# ESP32-H4 register map
Vendor: ESPRESSIF SYSTEMS (SHANGHAI) CO., LTD.; Series: ESP32 H-Series; File version: 1
CPU: RV32IMAC r0p0, little endian, no MPU, no FPU, 0 interrupt priority bits
Address unit: 32 bits
Registers are 32-bit, read-write, reset 0x0 unless marked. A register's access mark holds for its fields unless they carry their own. Offsets are from the block's base; [hi:lo] are bit positions; 'fields as' and 'values as' point back to an identical list; <NAME> marks a mode.

## USB0 (part 2 of 4) — USB OTG (On-The-Go)
Base 0x60040000
Same registers: USB1 0x6007F000
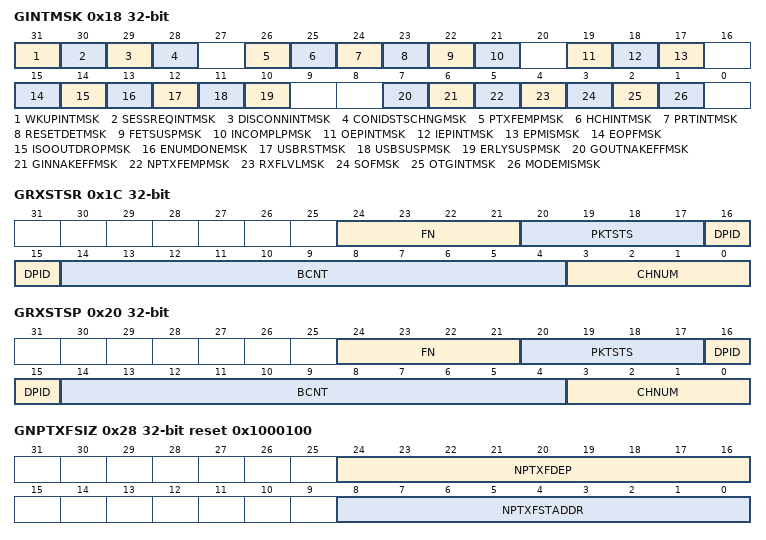
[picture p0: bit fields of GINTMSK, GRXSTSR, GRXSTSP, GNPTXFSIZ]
0x18 GINTMSK — Interrupt Mask Register This register works with the Interrupt Register (GINTSTS) to interrupt the application. When an interrupt bit is masked, the interrupt associated with that bit is not generated. However, the GINTSTS register bit corresponding to that interrupt is still set. Note: The fields of this register change depending on host or device mode.
  [31] WKUPINTMSK — Mode: Host and Device Resume/Remote Wakeup Detected Interrupt Mask (WkUpIntMsk) The WakeUp bit is used for LPM state wake up in a way similar to that of wake up in suspend state.
  [30] SESSREQINTMSK — Mode: Host and Device Session Request/New Session Detected Interrupt Mask (SessReqIntMsk)
  [29] DISCONNINTMSK — Mode: Host and Device Disconnect Detected Interrupt Mask (DisconnIntMsk)
  [28] CONIDSTSCHNGMSK — Mode: Host and Device Connector ID Status Change Mask (ConIDStsChngMsk)
  [26] PTXFEMPMSK — Mode: Host only Periodic TxFIFO Empty Mask (PTxFEmpMsk)
  [25] HCHINTMSK — Mode: Host only Host Channels Interrupt Mask (HChIntMsk)
  [24] PRTINTMSK — Mode: Host only Host Port Interrupt Mask (PrtIntMsk)
  [23] RESETDETMSK — Mode: Device only Reset detected Interrupt Mask (ResetDetMsk)
  [22] FETSUSPMSK — Mode: Device only Data Fetch Suspended Mask (FetSuspMsk)
  [21] INCOMPLPMSK — Incomplete Periodic Transfer Mask (incomplPMsk) Mode: Host only Incomplete Isochronous OUT Transfer Interrupt Mask (incompISOOUTMsk) Mode: Device only
  [19] OEPINTMSK — Mode: Device only OUT Endpoints Interrupt Mask (OEPIntMsk)
  [18] IEPINTMSK — Mode: Device only IN Endpoints Interrupt Mask (IEPIntMsk)
  [17] EPMISMSK — Mode: Device only Endpoint Mismatch Interrupt Mask (EPMisMsk)
  [15] EOPFMSK — Mode: Device only End of Periodic Frame Interrupt Mask (EOPFMsk)
  [14] ISOOUTDROPMSK — Mode: Device only Isochronous OUT Packet Dropped Interrupt Mask (ISOOutDropMsk)
  [13] ENUMDONEMSK — Mode: Device only Enumeration Done Mask (EnumDoneMsk)
  [12] USBRSTMSK — Mode: Device only USB Reset Mask (USBRstMsk)
  [11] USBSUSPMSK — Mode: Device only USB Suspend Mask (USBSuspMsk)
  [10] ERLYSUSPMSK — Mode: Device only Early Suspend Mask (ErlySuspMsk)
  [7] GOUTNAKEFFMSK — Mode: Device only Global OUT NAK Effective Mask (GOUTNakEffMsk)
  [6] GINNAKEFFMSK — Mode: Device only, Global Non-periodic IN NAK Effective Mask (GINNakEffMsk)
  [5] NPTXFEMPMSK — Mode: Host and Device Non-periodic TxFIFO Empty Mask (NPTxFEmpMsk)
  [4] RXFLVLMSK — Mode: Host and Device Receive FIFO Non-Empty Mask (RxFLvlMsk)
  [3] SOFMSK — Mode: Host and Device Start of (micro)Frame Mask (SofMsk)
  [2] OTGINTMSK — Mode: Host and Device OTG Interrupt Mask (OTGIntMsk)
  [1] MODEMISMSK — Mode: Host and Device Mode Mismatch Interrupt Mask (ModeMisMsk)
0x1C GRXSTSR ro — Receive Status Debug Read Register A read to the Receive Status Debug Read register returns the contents of the top of the Receive FIFO. The receive status contents must be interpreted differently in Host and Device modes. The core ignores the receive status read when the receive FIFO is empty and returns a value of 32'h0000_0000. Note: - Use of these fields vary based on whether the core is functioning as a host or a device. - Do not read this register's reset value before configuring the core because the read value is 'X' in the simulation.
  [24:21] FN — Mode: Device only Frame Number (FN) This is the least significant 4 bits of the (micro)Frame number in which the packet is received on the USB. This field is supported only when isochronous OUT endpoints are supported.
  [20:17] PKTSTS — Packet Status (PktSts) indicates the status of the received packet. In host mode, - 4'b0010: IN data packet received - 4'b0011: IN transfer completed (triggers an interrupt) - 4'b0101: Data toggle error (triggers an interrupt) - 4'b0111: Channel halted (triggers an interrupt) - Others: Reserved Reset:4'b0 In device mode, - 4'b0001: Global OUT NAK (triggers an interrupt) - 4'b0010: OUT data packet received - 4'b0011: OUT transfer completed (triggers an interrupt) - 4'b0100: SETUP transaction completed (triggers an interrupt) - 4'b0110: SETUP data packet received - Others: Reserved Reset:4'h0
  [16:15] DPID — Data PID (DPID) In host mode, indicates the Data PID of the received packet. In device mode, indicates the Data PID of the received OUT data packet. - 2'b00: DATA0 - 2'b10: DATA1 - 2'b01: DATA2 - 2'b11: MDATA Reset: 2'h0
  [14:4] BCNT — Byte Count (BCnt) In host mode, indicates the byte count of the received IN data packet. In device mode, indicates the byte count of the received data packet.
  [3:0] CHNUM — Channel Number (ChNum) Mode: Host only Indicates the channel number to which the current received packet belongs. Endpoint Number (EPNum) Mode: Device only Indicates the endpoint number to which the current received packet belongs.
0x20 GRXSTSP ro — Receive Status Read/Pop Register A read to the Receive Status Read and Pop register returns the contents of the top of the Receive FIFO and additionally pops the top data entry out of the RxFIFO. The receive status contents must be interpreted differently in Host and Device modes. The core ignores the receive status pop/read when the receive FIFO is empty and returns a value of 32'h0000_0000. The application must only pop the Receive Status FIFO when the Receive FIFO Non-Empty bit of the Core Interrupt register (GINTSTS.RxFLvl) is asserted. Note: - Use of these fields vary based on whether the core is functioning as a host or a device. - Do not read this register's reset value before configuring the core because the read value is 'X' in the simulation.
  fields as GRXSTSR
0x24 GRXFSIZ reset 0x100 — Receive FIFO Size Register The application can program the RAM size that must be allocated to the RxFIFO.
  [8:0] RXFDEP — Mode: Host and Device RxFIFO Depth (RxFDep) This value is in terms of 32-bit words. - Minimum value is 16 - Maximum value is 32,768 The power-on reset value of this register is specified as the Largest Rx Data FIFO Depth during configuration. If Enable Dynamic FIFO Sizing is selected in coreConsultant, these flops are optimized, and reads return the power-on value. If Enable Dynamic FIFO Sizing is selected in coreConsultant, you can write a new value in this field. Programmed values must not exceed the power-on value.
0x28 GNPTXFSIZ reset 0x1000100 — Non-periodic Transmit FIFO Size Register The application can program the RAM size and the memory start address for the Non-periodic TxFIFO Note: The fields of this register change depending on host or device mode.
  [24:16] NPTXFDEP — Mode: Host only Non-periodic TxFIFO Depth (NPTxFDep) For host mode, this field is always valid. For device mode, this field is valid only when OTG_EN_DED_TX_FIFO=0. This value is in terms of 32-bit words. - Minimum value is 16 - Maximum value is 32,768 This attribute of field is determined during coreConsultant configuration by Enable Dynamic FIFO Sizing? (OTG_DFIFO_DYNAMIC): - OTG_DFIFO_DYNAMIC = 0: These flops are optimized, and reads return the power-on value. - OTG_DFIFO_DYNAMIC = 1: The application can write a new value in this field. Programmed values must not exceed the power-on value set in coreConsultant. The power-on reset value of this field is specified during coreConsultant configuration as Largest IN Endpoint FIFO 0 Depth (parameter OTG_TX_DINEP_DFIFO_DEPTH_0).
  [8:0] NPTXFSTADDR — Non-periodic Transmit RAM Start Address (NPTxFStAddr) For host mode, this field is always valid. This field contains the memory start address for Non-periodic Transmit FIFO RAM. - This field is determined during coreConsultant configuration by Enable Dynamic FIFO Sizing? (OTG_DFIFO_DYNAMIC):OTG_DFIFO_DYNAMIC = 0 These flops are optimized, and reads return the power-on value. - OTG_DFIFO_DYNAMIC = 1 The application can write a new value in this field. Programmed values must not exceed the power-on value set in coreConsultant. Programmed values must not exceed the power-on value set in coreConsultant. The power-on reset value of this field is specified during coreConsultant configuration by Largest Rx Data FIFO Depth (parameter OTG_RX_DFIFO_DEPTH).
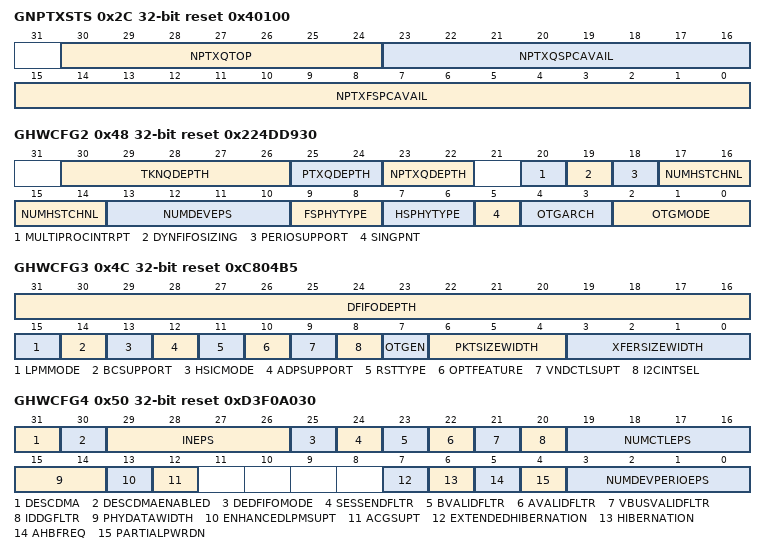
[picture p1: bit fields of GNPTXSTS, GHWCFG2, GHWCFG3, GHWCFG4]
0x2C GNPTXSTS ro reset 0x40100 — Non-periodic Transmit FIFO/Queue Status Register In Device mode, this register is valid only in Shared FIFO operation. This read-only register contains the free space information for the Non-periodic TxFIFO and the Non-periodic Transmit Request Queue.
  [30:24] NPTXQTOP — Top of the Non-periodic Transmit Request Queue (NPTxQTop) Entry in the Non-periodic Tx Request Queue that is currently being processed by the MAC. - Bits [30:27]: Channel/endpoint number - Bits [26:25]: - 2'b00: IN/OUT token -- 2'b01: Zero-length transmit packet (device IN/host OUT) -- 2'b10: PING/CSPLIT token -- 2'b11: Channel halt command - Bit [24]: Terminate (last Entry for selected channel/endpoint) Reset: 7'h0
  [23:16] NPTXQSPCAVAIL — Non-periodic Transmit Request Queue Space Available (NPTxQSpcAvail) Indicates the amount of free space available in the Non-periodic Transmit Request Queue. This queue holds both IN and OUT requests in Host mode. Device mode has only IN requests. - 8'h0: Non-periodic Transmit Request Queue is full - 8'h1: 1 location available - 8'h2: 2 locations available - n: n locations available (0 <= n <= 8) - Others: Reserved Reset: Configurable
  [15:0] NPTXFSPCAVAIL — Non-periodic TxFIFO Space Avail (NPTxFSpcAvail) Indicates the amount of free space available in the Non-periodic TxFIFO. Values are in terms of 32-bit words. - 16'h0: Non-periodic TxFIFO is full - 16'h1: 1 word available - 16'h2: 2 words available - 16'hn: n words available (where 0 <= n <= 32,768) - 16'h8000: 32,768 words available - Others: Reserved Reset: Configurable
0x40 GSNPSID ro reset 0x4F54400A — Synopsys ID Register This read-only register contains the release number of the core being used.
  [31:0] SYNOPSYSID — Release number of the controller being used currently.
0x44 GHWCFG1 ro — User Hardware Configuration 1 Register This register contains the logical endpoint direction(s) selected using coreConsultant.
  [31:0] EPDIR — This 32-bit field uses two bits per endpoint to determine the endpoint direction. Endpoint - Bits [31:30]: Endpoint 15 direction - Bits [29:28]: Endpoint 14 direction ... - Bits [3:2]: Endpoint 1 direction - Bits[1:0]: Endpoint 0 direction (always BIDIR) Direction - 2'b00: BIDIR (IN and OUT) endpoint - 2'b01: IN endpoint - 2'b10: OUT endpoint - 2'b11: Reserved Note: This field is configured using the OTG_EP_DIR_1(n) parameter.
0x48 GHWCFG2 ro reset 0x224DD930 — User Hardware Configuration 2 Register This register contains configuration options selected using coreConsultant.
  [30:26] TKNQDEPTH — Device Mode IN Token Sequence Learning Queue Depth (TknQDepth) Range: 0-30 Note: This field is configured using the OTG_TOKEN_QUEUE_DEPTH parameter.
  [25:24] PTXQDEPTH — Host Mode Periodic Request Queue Depth (PTxQDepth) - 2'b00: 2 - 2'b01: 4 - 2'b10: 8 - 2'b11:16 Note: This field is configured using the OTG_PERIO_TX_QUEUE_DEPTH parameter.
  [23:22] NPTXQDEPTH — Non-periodic Request Queue Depth (NPTxQDepth) - 2'b00: 2 - 2'b01: 4 - 2'b10: 8 - Others: Reserved Note: This field is configured using the OTG_NPERIO_TX_QUEUE_DEPTH parameter.
  [20] MULTIPROCINTRPT — Multi Processor Interrupt Enabled (MultiProcIntrpt) - 1'b0: No - 1'b1: Yes Note: This field is configured using the OTG_MULTI_PROC_INTRPT parameter.
  [19] DYNFIFOSIZING — Dynamic FIFO Sizing Enabled (DynFifoSizing) - 1'b0: No - 1'b1: Yes Note: This field is configured using the OTG_DFIFO_DYNAMIC parameter.
  [18] PERIOSUPPORT — Periodic OUT Channels Supported in Host Mode (PerioSupport) - 1'b0: No - 1'b1: Yes Note: This field is configured using the OTG_EN_PERIO_HOST parameter.
  [17:14] NUMHSTCHNL — Number of Host Channels (NumHstChnl) Indicates the number of host channels supported by the core in Host mode. The range of this field is 0-15: 0 specifies 1 channel, 15 specifies 16 channels. Note: This field is configured using the OTG_NUM_HOST_CHAN parameter.
  [13:10] NUMDEVEPS — Number of Device Endpoints (NumDevEps) Indicates the number of device endpoints supported by the core in Device mode. The range of this field is 0-15. Note: This field is configured using the OTG_NUM_EPS parameter.
  [9:8] FSPHYTYPE — Full-Speed PHY Interface Type (FSPhyType) - 2'b00: Full-speed interface not supported - 2'b01: Dedicated full-speed interface - 2'b10: FS pins shared with UTMI+ pins - 2'b11: FS pins shared with ULPI pins Note: This field is configured using the OTG_FSPHY_INTERFACE parameter.
  [7:6] HSPHYTYPE — High-Speed PHY Interface Type (HSPhyType) - 2'b00: High-Speed interface not supported - 2'b01: UTMI+ - 2'b10: ULPI - 2'b11: UTMI+ and ULPI Note: This field is configured using the OTG_HSPHY_INTERFACE parameter.
  [5] SINGPNT — Point-to-Point (SingPnt) - 1'b0: Multi-point application (hub and split support) - 1'b1: Single-point application (no hub and split support) Note: This field is configured using the OTG_SINGLE_POINT parameter.
  [4:3] OTGARCH — Architecture (OtgArch) - 2'b00: Slave-Only - 2'b01: External DMA - 2'b10: Internal DMA - Others: Reserved Note: This field is configured using the OTG_ARCHITECTURE parameter.
  [2:0] OTGMODE — Mode of Operation (OtgMode) - 3'b000: HNP- and SRP-Capable OTG (Host & Device) - 3'b001: SRP-Capable OTG (Host & Device) - 3'b010: Non-HNP and Non-SRP Capable OTG (Host and Device) - 3'b011: SRP-Capable Device - 3'b100: Non-OTG Device - 3'b101: SRP-Capable Host - 3'b110: Non-OTG Host - Others: Reserved Note: This field is configured using the OTG_MODE parameter.
0x4C GHWCFG3 ro reset 0xC804B5 — User Hardware Configuration 3 Register
  [31:16] DFIFODEPTH — DFIFO Depth (DfifoDepth - EP_LOC_CNT) This value is in terms of 32-bit words. - Minimum value is 32 - Maximum value is 32,768 Note: This field is configured using the OTG_DFIFO_DEPTH parameter. For more information on EP_LOC_CNT, see the Endpoint Information Controller (EPINFO_CTL) section.
  [15] LPMMODE — LPM mode specified for Mode of Operation.
  [14] BCSUPPORT — This bit indicates the controller support for Battery Charger. - 0 - No Battery Charger Support - 1 - Battery Charger support present
  [13] HSICMODE — HSIC mode specified for Mode of Operation Value Range: 0 - 1 - 1: HSIC-capable with shared UTMI PHY interface - 0: Non-HSIC-capable
  [12] ADPSUPPORT — This bit indicates whether ADP logic is present within or external to the controller - 0: No ADP logic present with the controller - 1: ADP logic is present along with the controller.
  [11] RSTTYPE — Reset Style for Clocked always Blocks in RTL (RstType) - 1'b0: Asynchronous reset is used in the controller - 1'b1: Synchronous reset is used in the controller Note: This field is configured using the OTG_SYNC_RESET_TYPE parameter.
  [10] OPTFEATURE — Optional Features Removed (OptFeature) Indicates whether the User ID register, GPIO interface ports, and SOF toggle and counter ports were removed for gate count optimization by enabling Remove Optional Features. - 1'b0: No - 1'b1: Yes Note: This field is configured using the OTG_RM_OPT_FEATURES parameter.
  [9] VNDCTLSUPT — Vendor Control Interface Support (VndctlSupt) - 1'b0: Vendor Control Interface is not available on the core. - 1'b1: Vendor Control Interface is available. Note: This field is configured using the OTG_VENDOR_CTL_INTERFACE parameter.
  [8] I2CINTSEL — I2C Selection (I2CIntSel) - 1'b0: I2C Interface is not available on the controller. - 1'b1: I2C Interface is available on the controller. Note: This field is configured using the OTG_I2C_INTERFACE parameter.
  [7] OTGEN — OTG Function Enabled (OtgEn) The application uses this bit to indicate the OTG capabilities of the controller . - 1'b0: Not OTG capable - 1'b1: OTG Capable Note: This field is configured using the OTG_MODE parameter.
  [6:4] PKTSIZEWIDTH — Width of Packet Size Counters (PktSizeWidth) - 3'b000: 4 bits - 3'b001: 5 bits - 3'b010: 6 bits - 3'b011: 7 bits - 3'b100: 8 bits - 3'b101: 9 bits - 3'b110: 10 bits - Others: Reserved Note: This field is configured using the OTG_PACKET_COUNT_WIDTH parameter.
  [3:0] XFERSIZEWIDTH — Width of Transfer Size Counters (XferSizeWidth) - 4'b0000: 11 bits - 4'b0001: 12 bits ... - 4'b1000: 19 bits - Others: Reserved Note: This field is configured using the OTG_PACKET_COUNT_WIDTH parameter.
0x50 GHWCFG4 ro reset 0xD3F0A030 — User Hardware Configuration 4 Register Note Bit [31] is available only when Scatter/Gather DMA mode is enabled. When Scatter/Gather DMA mode is disabled, this field is reserved.
  [31] DESCDMA — Scatter/Gather DMA configuration - 1'b0: Non Dynamic configuration - 1'b1: Dynamic configuration Note: This field is configured using the OTG_EN_DESC_DMA parameter.
  [30] DESCDMAENABLED — Scatter/Gather DMA configuration - 1'b0: Non-Scatter/Gather DMA configuration - 1'b1: Scatter/Gather DMA configuration
  [29:26] INEPS — Number of Device Mode IN Endpoints Including Control Endpoints (INEps) - 0: 1 IN Endpoint - 1: 2 IN Endpoints .... - 15: 16 IN Endpoints
  [25] DEDFIFOMODE — Enable Dedicated Transmit FIFO for device IN Endpoints (DedFifoMode) - 1'b0 : Dedicated Transmit FIFO Operation not enabled. - 1'b1 : Dedicated Transmit FIFO Operation enabled.
  [24] SESSENDFLTR — session_end Filter Enabled (SessEndFltr) - 1'b0: No filter - 1'b1: Filter
  [23] BVALIDFLTR — b_valid Filter Enabled (BValidFltr) - 1'b0: No filter - 1'b1: Filter
  [22] AVALIDFLTR — a_valid Filter Enabled (AValidFltr) - 1'b0: No filter - 1'b1: Filter
  [21] VBUSVALIDFLTR — VBUS Valid Filter Enabled (VBusValidFltr) - 1'b0: No filter - 1'b1: Filter
  [20] IDDGFLTR — IDDIG Filter Enable (IddgFltr) - 1'b0: No filter - 1'b1: Filter
  [19:16] NUMCTLEPS — Number of Device Mode Control Endpoints in Addition to Endpoint 0 (NumCtlEps) Range: 0-15
  [15:14] PHYDATAWIDTH — UTMI+ PHY/ULPI-to-Internal UTMI+ Wrapper Data Width (PhyDataWidth)<vr>When a ULPI PHY is used, an internal wrapper converts ULPI to UTMI+. - 2'b00: 8 bits - 2'b01: 16 bits - 2'b10: 8/16 bits, software selectable - Others: Reserved
  [13] ENHANCEDLPMSUPT — Enhanced LPM Support (EnhancedLPMSupt) This bit indicates that the controller supports the following behavior: L1 Entry Behavior based on FIFO Status - TX FIFO - Accept L1 Request even if ISOC OUT TX FIFO is not empty. - Reject L1 Request if Non-Periodic TX FIFO is not empty. - Ensure application can flush the TX FIFO while the Controller is in L1. - RX FIFO - Accept L1 Request even if RX FIFO (common to Periodic and Non-Periodic) is not empty. - Accept L1 Request but delay SLEEPM assertion until RX SINK Buffer is empty. Prevent L1 Entry if a Control Transfer is in progress on any Control Endpoint. Ability to Flush TxFIFO even if PHY Clock is gated.
  [12] ACGSUPT — Active Clock Gating Support This bit indicates that the controller supports the Dynamic (Switching) Power Reduction during periods when there is no USB and AHB Traffic. - 1'b0: Active Clock Gating is not enabled. - 1'b1: Active Clock Gating Enabled.
  [7] EXTENDEDHIBERNATION — Enable Hibernation - 1'b0: Extended Hibernation feature not enabled - 1'b1: Extended Hibernation feature enabled
  [6] HIBERNATION — Enable Hibernation (Hibernation) - 1'b0: Hibernation feature not enabled - 1'b1: Hibernation feature enabled
  [5] AHBFREQ — Minimum AHB Frequency Less Than 60 MHz (AhbFreq) - 1'b0: No - 1'b1: Yes
  [4] PARTIALPWRDN — Enable Partial Power Down (PartialPwrDn) - 1'b0: Partial Power Down Not Enabled - 1'b1: Partial Power Down Enabled
  [3:0] NUMDEVPERIOEPS — Number of Device Mode Periodic IN Endpoints (NumDevPerioEps) Range: 0-15
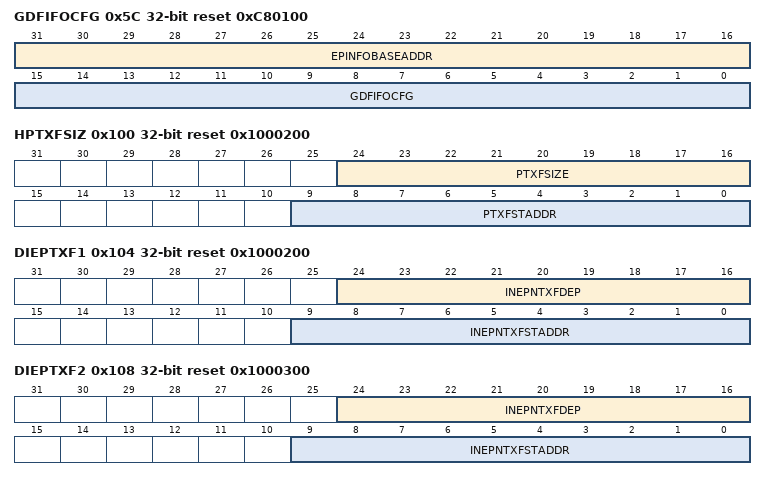
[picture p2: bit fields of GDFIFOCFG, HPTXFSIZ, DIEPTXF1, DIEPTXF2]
0x5C GDFIFOCFG reset 0xC80100 — Global DFIFO Configuration Register
  [31:16] EPINFOBASEADDR — EPInfoBaseAddr This field provides the start address of the EP info controller.
  [15:0] GDFIFOCFG — GDFIFOCfg This field is for dynamic programming of the DFIFO Size. This value takes effect only when the application programs a non zero value to this register. The value programmed must conform to the guidelines described in 'FIFO RAM Allocation'. The core does not have any corrective logic if the FIFO sizes are programmed incorrectly.
0x100 HPTXFSIZ reset 0x1000200 — Host Periodic Transmit FIFO Size Register This register holds the size and the memory start address of the Periodic TxFIFO. Note: Read the reset value of this register only after the following conditions: - If IDDIG_FILTER is disabled, read only after PHY clock is stable. - If IDDIG_FILTER is enabled, read only after the filter timer expires.
  [24:16] PTXFSIZE — Host Periodic TxFIFO Depth (PTxFSize) This value is in terms of 32-bit words. - Minimum value is 16 - Maximum value is 32,768 The power-on reset value of this register is specified as the Largest Host Mode Periodic Tx Data FIFO Depth. - If Enable Dynamic FIFO Sizing? was deselected in coreConsultant (parameter OTG_DFIFO_DYNAMIC = 0), these flops are optimized, and reads return the power-on value. - If Enable Dynamic FIFO Sizing? was selected in coreConsultant (parameter OTG_DFIFO_DYNAMIC = 1), you can write a new value in this field. Programmed values must not exceed the power-on value set in coreConsultant.
  [9:0] PTXFSTADDR — Host Periodic TxFIFO Start Address (PTxFStAddr) The power-on reset value of this register is the sum of the Largest Rx Data FIFO Depth and Largest Non-periodic Tx Data FIFO Depth.These parameters are: In shared FIFO operation: - OTG_RX_DFIFO_DEPTH + OTG_TX_NPERIO_DFIFO_DEPTH In dedicated FIFO mode: - OTG_RX_DFIFO_DEPTH + OTG_TX_HNPERIO_DFIFO_DEPTH If Enable Dynamic FIFO Sizing? was deselected in coreConsultant (parameter OTG_DFIFO_DYNAMIC = 0), these flops are optimized, and reads return the power-on value. If Enable Dynamic FIFO Sizing? was selected in coreConsultant (parameter OTG_DFIFO_DYNAMIC = 1), you can write a new value in this field. Programmed values must not exceed the power-on value set in coreConsultant.
0x104 DIEPTXF1 reset 0x1000200 — Device IN Endpoint Transmit FIFO Size Register $i This register is valid only in dedicated FIFO mode (OTG_EN_DED_TX_FIFO=1). It holds the size and memory start address of IN endpoint TxFIFOs implemented in Device mode. Each FIFO holds the data for one IN endpoint. This register is repeated for instantiated IN endpoint FIFOs 1 to 15. For IN endpoint FIFO 0, use GNPTXFSIZ register for programming the size and memory start address.
  [24:16] INEPNTXFDEP — IN Endpoint TxFIFO Depth (INEPnTxFDep) This value is in terms of 32-bit words. - Minimum value is 16 - Maximum value is 32,768 The power-on reset value of this register is specified as the Largest IN Endpoint FIFO number Depth (parameter OTG_TX_DINEP_DFIFO_DEPTH_n) during coreConsultant configuration (0 < i <= 15). - If Enable Dynamic FIFO Sizing? was deselected in coreConsultant (parameter OTG_DFIFO_DYNAMIC = 0), these flops are optimized, and reads return the power-on value. - If Enable Dynamic FIFO Sizing? was selected in coreConsultant (parameter OTG_DFIFO_DYNAMIC = 1), you can write a new value in this field. . Programmed values must not exceed the power-on value
  [9:0] INEPNTXFSTADDR — IN Endpoint FIFOn Transmit RAM Start Address (INEPnTxFStAddr) This field contains the memory start address for IN endpoint Transmit FIFOn (0<n< = 15). The power-on reset value of this register is specified as the Largest Rx Data FIFO Depth. The power-on reset value of this register is calculated according to the following formula: OTG_RX_DFIFO_DEPTH + SUM of OTG_TX_DINEP_DFIFO_DEPTH_'i' (where x = 0 to n 1) If at POR the calculated value (C) exceeds 65535, then the Reset value becomes Reset Value(A) = (C 65536). Example: If start address of IN endpoint FIFO 1 is OTG_RX_DFIFO_DEPTH + OTG_TX_DINEP_DFIFO_DEPTH_ 0 and start address of IN endpoint FIFO 2 is OTG_RX_DFIFO_DEPTH + OTG_TX_DINEP_DFIFO_DEPTH_ 0 + OTG_TX_DINEP_DFIFO_DEPTH_ 1. - If Enable Dynamic FIFO Sizing is deselected in coreConsultant (OTG_DFIFO_DYNAMIC = 0), this field is read-only and read value is the power-on reset value. - If Enable Dynamic FIFO Sizing is selected in coreConsultant (OTG_DFIFO_DYNAMIC = 1), and you have calculated or programmed a new value for RxFIFO depth or TX FIFO depths, you can program their values according to the above formula. Programmed values must not exceed the power-on value set in coreConsultant.
0x108 DIEPTXF2 reset 0x1000300 — Device IN Endpoint Transmit FIFO Size Register $i This register is valid only in dedicated FIFO mode (OTG_EN_DED_TX_FIFO=1). It holds the size and memory start address of IN endpoint TxFIFOs implemented in Device mode. Each FIFO holds the data for one IN endpoint. This register is repeated for instantiated IN endpoint FIFOs 1 to 15. For IN endpoint FIFO 0, use GNPTXFSIZ register for programming the size and memory start address.
  fields as DIEPTXF1
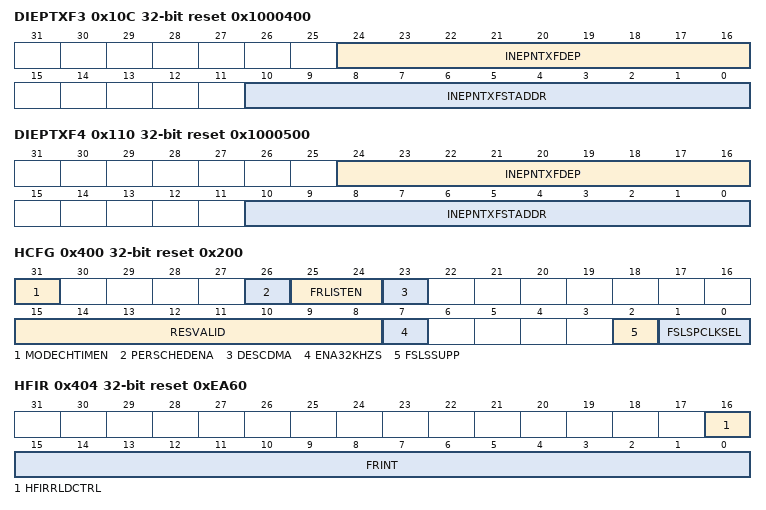
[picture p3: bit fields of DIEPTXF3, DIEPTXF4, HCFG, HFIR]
0x10C DIEPTXF3 reset 0x1000400 — Device IN Endpoint Transmit FIFO Size Register $i This register is valid only in dedicated FIFO mode (OTG_EN_DED_TX_FIFO=1). It holds the size and memory start address of IN endpoint TxFIFOs implemented in Device mode. Each FIFO holds the data for one IN endpoint. This register is repeated for instantiated IN endpoint FIFOs 1 to 15. For IN endpoint FIFO 0, use GNPTXFSIZ register for programming the size and memory start address.
  [24:16] INEPNTXFDEP — IN Endpoint TxFIFO Depth (INEPnTxFDep) This value is in terms of 32-bit words. - Minimum value is 16 - Maximum value is 32,768 The power-on reset value of this register is specified as the Largest IN Endpoint FIFO number Depth (parameter OTG_TX_DINEP_DFIFO_DEPTH_n) during coreConsultant configuration (0 < i <= 15). - If Enable Dynamic FIFO Sizing? was deselected in coreConsultant (parameter OTG_DFIFO_DYNAMIC = 0), these flops are optimized, and reads return the power-on value. - If Enable Dynamic FIFO Sizing? was selected in coreConsultant (parameter OTG_DFIFO_DYNAMIC = 1), you can write a new value in this field. . Programmed values must not exceed the power-on value
  [10:0] INEPNTXFSTADDR — IN Endpoint FIFOn Transmit RAM Start Address (INEPnTxFStAddr) This field contains the memory start address for IN endpoint Transmit FIFOn (0<n< = 15). The power-on reset value of this register is specified as the Largest Rx Data FIFO Depth. The power-on reset value of this register is calculated according to the following formula: OTG_RX_DFIFO_DEPTH + SUM of OTG_TX_DINEP_DFIFO_DEPTH_'i' (where x = 0 to n 1) If at POR the calculated value (C) exceeds 65535, then the Reset value becomes Reset Value(A) = (C 65536). Example: If start address of IN endpoint FIFO 1 is OTG_RX_DFIFO_DEPTH + OTG_TX_DINEP_DFIFO_DEPTH_ 0 and start address of IN endpoint FIFO 2 is OTG_RX_DFIFO_DEPTH + OTG_TX_DINEP_DFIFO_DEPTH_ 0 + OTG_TX_DINEP_DFIFO_DEPTH_ 1. - If Enable Dynamic FIFO Sizing is deselected in coreConsultant (OTG_DFIFO_DYNAMIC = 0), this field is read-only and read value is the power-on reset value. - If Enable Dynamic FIFO Sizing is selected in coreConsultant (OTG_DFIFO_DYNAMIC = 1), and you have calculated or programmed a new value for RxFIFO depth or TX FIFO depths, you can program their values according to the above formula. Programmed values must not exceed the power-on value set in coreConsultant.
0x110 DIEPTXF4 reset 0x1000500 — Device IN Endpoint Transmit FIFO Size Register $i This register is valid only in dedicated FIFO mode (OTG_EN_DED_TX_FIFO=1). It holds the size and memory start address of IN endpoint TxFIFOs implemented in Device mode. Each FIFO holds the data for one IN endpoint. This register is repeated for instantiated IN endpoint FIFOs 1 to 15. For IN endpoint FIFO 0, use GNPTXFSIZ register for programming the size and memory start address.
  fields as DIEPTXF3
0x400 HCFG reset 0x200 — Host Configuration Register
  [31] MODECHTIMEN — Mode Change Ready Timer Enable (ModeChTimEn) This bit is used to enable/disable the Host core to wait 200 PHY clock cycles at the end of Resume to change the opmode signal to the PHY to 00 after Suspend or LPM. - 1'b0 : The Host core waits for either 200 PHY clock cycles or a linestate of SE0 at the end of resume to the change the opmode from 2'b10 to 2'b00 - 1'b1 : The Host core waits only for a linstate of SE0 at the end of resume to change the opmode from 2'b10 to 2'b00.
  [26] PERSCHEDENA — Enable Periodic Scheduling (PerSchedEna): Applicable in host DDMA mode only. Enables periodic scheduling within the core. Initially, the bit is reset. The core will not process any periodic channels. As soon as this bit is set, the core will get ready to start scheduling periodic channels and sets HCFG.PerSchedStat. The setting of HCFG.PerSchedStat indicates the core has enabled periodic scheduling. Once HCFG.PerSchedEna is set, the application is not supposed to again reset the bit unless HCFG.PerSchedStat is set. As soon as this bit is reset, the core will get ready to stop scheduling periodic channels and resets HCFG.PerSchedStat.
  [25:24] FRLISTEN — Frame List Entries(FrListEn) The value in the register specifies the number of entries in the Frame list. This field is valid only in Scatter/Gather DMA mode. - 2'b00: 8 Entries - 2'b01: 16 Entries - 2'b10: 32 Entries - 2'b11: 64 Entries
  [23] DESCDMA — Enable Scatter/gather DMA in Host mode (DescDMA) When the Scatter/Gather DMA option selected during configuration of the RTL, the application can set this bit during initialization to enable the Scatter/Gather DMA operation. Note: This bit must be modified only once after a reset. The following combinations are available for programming: - GAHBCFG.DMAEn=0,HCFG.DescDMA=0 => Slave mode - GAHBCFG.DMAEn=0,HCFG.DescDMA=1 => Invalid - GAHBCFG.DMAEn=1,HCFG.DescDMA=0 => Buffered DMA mode - GAHBCFG.DMAEn=1,HCFG.DescDMA=1 => Scatter/Gather DMA mode
  [15:8] RESVALID — Resume Validation Period (ResValid) This field is effective only when HCFG.Ena32KHzS is set. It will control the resume period when the core resumes from suspend. The core counts for 'ResValid' number of clock cycles to detect a valid resume when this is set.
  [7] ENA32KHZS — Enable 32 KHz Suspend mode (Ena32KHzS) This bit can be set only in FS PHY interface is selected. Else, this bit needs to be set to zero. When FS PHY interface is chosen and this bit is set, the core expects that the PHY clock during Suspend is switched from 48 MHz to 32 KHz.
  [2] FSLSSUPP — FS- and LS-Only Support (FSLSSupp) The application uses this bit to control the core's enumeration speed. Using this bit, the application can make the core enumerate as a FS host, even If the connected device supports HS traffic. Do not make changes to this field after initial programming. - 1'b0: HS/FS/LS, based on the maximum speed supported by the connected device - 1'b1: FS/LS-only, even If the connected device can support HS
  [1:0] FSLSPCLKSEL — FS/LS PHY Clock Select (FSLSPclkSel) When the core is in FS Host mode - 2'b00: PHY clock is running at 30/60 MHz - 2'b01: PHY clock is running at 48 MHz - Others: Reserved When the core is in LS Host mode - 2'b00: PHY clock is running at 30/60 MHz. When the UTMI+/ULPI PHY Low Power mode is not selected, use 30/60 MHz. - 2'b01: PHY clock is running at 48 MHz. When the UTMI+ PHY Low Power mode is selected, use 48MHz If the PHY supplies a 48 MHz clock during LS mode. - 2'b10: PHY clock is running at 6 MHz. In USB 1.1 FS mode, use 6 MHz when the UTMI+ PHY Low Power mode is selected and the PHY supplies a 6 MHz clock during LS mode. If you select a 6 MHz clock during LS mode, you must do a soft reset. - 2'b11: Reserved Notes: - When Core in FS mode, the internal and external clocks have the same frequency. - When Core in LS mode, -- If FSLSPclkSel = 2'b00: Internal and external clocks have the same frequency -- If FSLSPclkSel = 2'b10: Internal clock is the divided by eight version of external 48 MHz clock
0x404 HFIR reset 0xEA60 — Host Frame Interval Register
  [16] HFIRRLDCTRL — Reload Control (HFIRRldCtrl) This bit allows dynamic reloading of the HFIR register during run time. - 1'b0 : The HFIR cannot be reloaded dynamically - 1'b1: the HFIR can be dynamically reloaded during runtime. This bit needs to be programmed during initial configuration and its value should not be changed during runtime.
  [15:0] FRINT — Frame Interval (FrInt) The value that the application programs to this field specifies the interval between two consecutive SOFs (FS) or micro- SOFs (HS) or Keep-Alive tokens (HS). This field contains the number of PHY clocks that constitute the required frame interval. The Default value set in this field is for FS operation when the PHY clock frequency is 60 MHz. The application can write a value to this register only after the Port Enable bit of the Host Port Control and Status register (HPRT.PrtEnaPort) has been Set. If no value is programmed, the core calculates the value based on the PHY clock specified in the FS/LS PHY Clock Select field of the Host Configuration register (HCFG.FSLSPclkSel). Do not change the value of this field after the initial configuration. - 125 s * (PHY clock frequency for HS) - 1 ms * (PHY clock frequency for FS/LS)
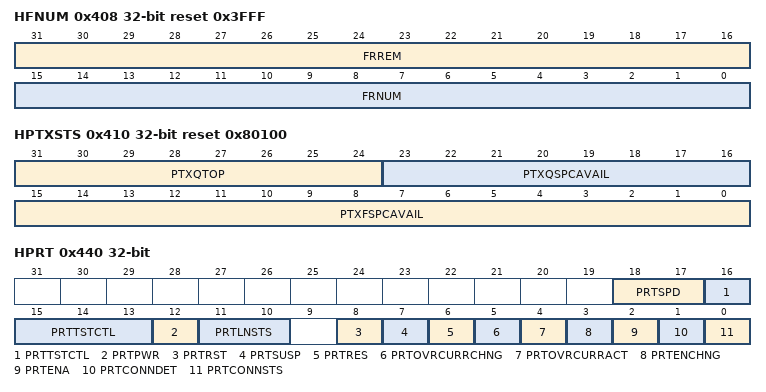
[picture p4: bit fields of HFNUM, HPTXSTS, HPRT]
0x408 HFNUM ro reset 0x3FFF — Host Frame Number/Frame Time Remaining Register This register indicates the current frame number. It also indicates the time remaining (in terms of the number of PHY clocks) in the current (micro)frame. Note: Read the reset value of this register only after the following conditions: - If IDDIG_FILTER is disabled, read only when the PHY clock is stable. - If IDDIG_FILTER is enabled, read only after the filter timer expires.
  [31:16] FRREM — Frame Time Remaining (FrRem) Indicates the amount of time remaining in the current microframe (HS) or Frame (FS/LS), in terms of PHY clocks. This field decrements on each PHY clock. When it reaches zero, this field is reloaded with the value in the Frame Interval register and a new SOF is transmitted on the USB.
  [15:0] FRNUM — Frame Number (FrNum) This field increments when a new SOF is transmitted on the USB, and is reset to 0 when it reaches 16'h3FFF.
0x410 HPTXSTS ro reset 0x80100 — Host Periodic Transmit FIFO/Queue Status Register
  [31:24] PTXQTOP — Top of the Periodic Transmit Request Queue (PTxQTop) This indicates the Entry in the Periodic Tx Request Queue that is currently being processes by the MAC. This register is used for debugging. - Bit [31]: Odd/Even (micro)Frame -- 1'b0: send in even (micro)Frame -- 1'b1: send in odd (micro)Frame - Bits [30:27]: Channel/endpoint number - Bits [26:25]: Type -- 2'b00: IN/OUT -- 2'b01: Zero-length packet -- 2'b10: CSPLIT -- 2'b11: Disable channel command - Bit [24]: Terminate (last Entry for the selected channel/endpoint)
  [23:16] PTXQSPCAVAIL — Periodic Transmit Request Queue Space Available (PTxQSpcAvail) Indicates the number of free locations available to be written in the Periodic Transmit Request Queue. This queue holds both IN and OUT requests. - 8'h0: Periodic Transmit Request Queue is full - 8'h1: 1 location available - 8'h2: 2 locations available - n: n locations available (0 <= n <= 16) - Others: Reserved
  [15:0] PTXFSPCAVAIL — Periodic Transmit Data FIFO Space Available (PTxFSpcAvail) Indicates the number of free locations available to be written to in the Periodic TxFIFO. Values are in terms of 32-bit words - 16'h0 : Periodic TxFIFO is full - 16'h1 : 1 word available - 16'h2 : 2 words available - 16'hn : n words available (where 0 n 32,768) - 16'h8000 : 32,768 words - Others : Reserved
0x414 HAINT ro — Host All Channels Interrupt Register When a significant event occurs on a channel, the Host All Channels Interrupt register interrupts the application using the Host Channels Interrupt bit of the Core Interrupt register (GINTSTS.HChInt). This is shown in the Interrupt Hierarchy figure in the databook. There is one interrupt bit per channel, up to a maximum of 16 bits. Bits in this register are set and cleared when the application sets and clears bits in the corresponding Host Channel-n Interrupt register.
  [7:0] HAINT — Channel Interrupt for channel no.
0x418 HAINTMSK — Host All Channels Interrupt Mask Register The Host All Channel Interrupt Mask register works with the Host All Channel Interrupt register to interrupt the application when an event occurs on a channel. There is one interrupt mask bit per channel, up to a maximum of 16 bits.
  [7:0] HAINTMSK — Channel Interrupt Mask (HAINTMsk) One bit per channel: Bit 0 for channel 0, bit 15 for channel 15
0x41C HFLBAddr — Host Frame List Base Address Register This register is present only in case of Scatter/Gather DMA. It is implemented as flops. This register holds the starting address of the Frame list information.
  [31:0] HFLBADDR_HFLBADDR — The starting address of the Frame list. This register is used only for Isochronous and Interrupt Channels.
0x440 HPRT access per field — Host Port Control and Status Register This register is available only in Host mode. Currently, the OTG Host supports only one port. A single register holds USB port-related information such as USB reset, enable, suspend, resume, connect status, and test mode for each port. It is shown in the Interrupt Hierarchy figure in the databook. The R_SS_WC bits in this register can trigger an interrupt to the application through the Host Port Interrupt bit of the Core Interrupt register (GINTSTS.PrtInt). On a Port Interrupt, the application must read this register and clear the bit that caused the interrupt. For the R_SS_WC bits, the application must write a 1 to the bit to clear the interrupt.
  [18:17] PRTSPD ro — Port Speed (PrtSpd) Indicates the speed of the device attached to this port. - 2'b00: High speed - 2'b01: Full speed - 2'b10: Low speed - 2'b11: Reserved
  [16:13] PRTTSTCTL rw — Port Test Control (PrtTstCtl) The application writes a nonzero value to this field to put the port into a Test mode, and the corresponding pattern is signaled on the port. - 4'b0000: Test mode disabled - 4'b0001: Test_J mode - 4'b0010: Test_K mode - 4'b0011: Test_SE0_NAK mode - 4'b0100: Test_Packet mode - 4'b0101: Test_Force_Enable - Others: Reserved To move the DWC_otg controller to test mode, you must set this field. Complete the following steps to move the DWC_otg core to test mode: - 1. Power on the core. - 2. Load the DWC_otg driver. - 3. Connect an HS device and enumerate to HS mode. - 4. Access the HPRT register to send test packets. - 5. Remove the device and connect to fixture (OPT) port. The DWC_otg host core continues sending out test packets. - 6. Test the eye diagram.
  [12] PRTPWR rw — Port Power (PrtPwr) The application uses this field to control power to this port (write 1'b1 to set to 1'b1 and write 1'b0 to set to 1'b0), and the core can clear this bit on an over current condition. - 1'b0: Power off - 1'b1: Power on Note: This bit is interface independent. The application needs to program this bit for all interfaces as described in the host programming flow in the Programming Guide.
  [11:10] PRTLNSTS ro — Port Line Status (PrtLnSts) Indicates the current logic level USB data lines - Bit [10]: Logic level of D+ - Bit [11]: Logic level of D-
  [8] PRTRST rw — Port Reset (PrtRst) When the application sets this bit, a reset sequence is started on this port. The application must time the reset period and clear this bit after the reset sequence is complete. - 1'b0: Port not in reset - 1'b1: Port in reset The application must leave this bit set for at least a minimum duration mentioned below to start a reset on the port. The application can leave it set for another 10 ms in addition to the required minimum duration, before clearing the bit, even though there is no maximum limit Set by the USB standard.This bit is cleared by the core even if there is no device connected to the Host. - High speed: 50 ms - Full speed/Low speed: 10 ms
  [7] PRTSUSP rw — Port Suspend (PrtSusp) The application sets this bit to put this port in Suspend mode. The core only stops sending SOFs when this is Set. To stop the PHY clock, the application must Set the Port Clock Stop bit, which asserts the suspend input pin of the PHY. The read value of this bit reflects the current suspend status of the port. This bit is cleared by the core after a remote wakeup signal is detected or the application sets the Port Reset bit or Port Resume bit in this register or the Resume/Remote Wakeup Detected Interrupt bit or Disconnect Detected Interrupt bit in the Core Interrupt register (GINTSTS.WkUpInt or GINTSTS.DisconnInt, respectively).This bit is cleared by the core even if there is no device connected to the Host. - 1'b0: Port not in Suspend mode - 1'b1: Port in Suspend mode
  [6] PRTRES rw — Port Resume (PrtRes) The application sets this bit to drive resume signaling on the port. The core continues to drive the resume signal until the application clears this bit. If the core detects a USB remote wakeup sequence, as indicated by the Port Resume/Remote Wakeup Detected Interrupt bit of the Core Interrupt register (GINTSTS.WkUpInt), the core starts driving resume signaling without application intervention and clears this bit when it detects a disconnect condition. The read value of this bit indicates whether the core is currently driving resume signaling. - 1'b0: No resume driven - 1'b1: Resume driven When LPM is enabled, In L1 state the behavior of this bit is as follows: The application sets this bit to drive resume signaling on the port. The core continues to drive the resume signal until a pre-determined time specified in GLPMCFG.HIRD_Thres[3:0] field. If the core detects a USB remote wakeup sequence, as indicated by the Port L1Resume/Remote L1Wakeup Detected Interrupt bit of the Core Interrupt register (GINTSTS.L1WkUpInt), the core starts driving resume signaling without application intervention and clears this bit at the end of resume.This bit can be set by both core or application and also cleared by core or application. This bit is cleared by the core even if there is no device connected to the Host.
  [5] PRTOVRCURRCHNG rw — Port Overcurrent Change (PrtOvrCurrChng) The core sets this bit when the status of the Port Overcurrent Active bit (bit 4) in this register changes.This bit can be set only by the core and the application should write 1 to clear it
  [4] PRTOVRCURRACT ro — Port Overcurrent Active (PrtOvrCurrAct) Indicates the overcurrent condition of the port. - 1'b0: No overcurrent condition - 1'b1: Overcurrent condition
  [3] PRTENCHNG rw — Port Enable/Disable Change (PrtEnChng) The core sets this bit when the status of the Port Enable bit [2] of this register changes.This bit can be set only by the core and the application should write 1 to clear it.
  [2] PRTENA rw — Port Enable (PrtEna) A port is enabled only by the core after a reset sequence, and is disabled by an overcurrent condition, a disconnect condition, or by the application clearing this bit. The application cannot Set this bit by a register write. It can only clear it to disable the port by writing 1. This bit does not trigger any interrupt to the application. - 1'b0: Port disabled - 1'b1: Port enabled
  [1] PRTCONNDET rw — Port Connect Detected (PrtConnDet) The core sets this bit when a device connection is detected to trigger an interrupt to the application using the Host Port Interrupt bit of the Core Interrupt register (GINTSTS.PrtInt).This bit can be set only by the core and the application should write 1 to clear it.The application must write a 1 to this bit to clear the interrupt.
  [0] PRTCONNSTS ro — Port Connect Status (PrtConnSts) - 0: No device is attached to the port. - 1: A device is attached to the port.
